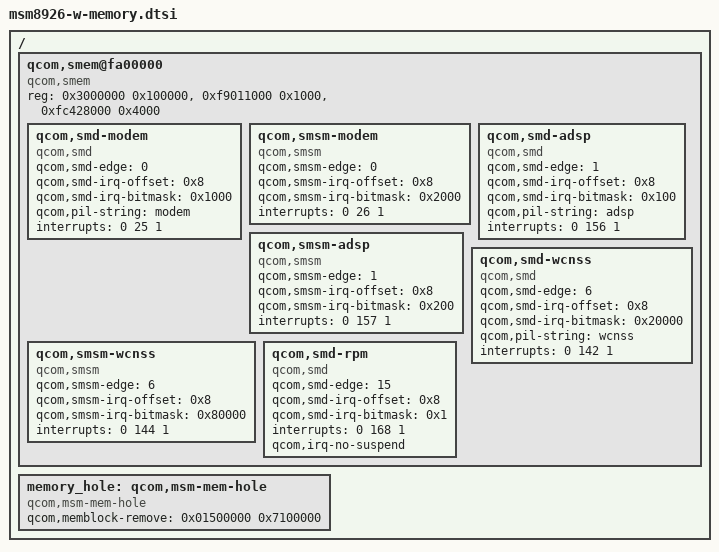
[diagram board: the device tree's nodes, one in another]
/* Copyright (c) 2015, The Linux Foundation. All rights reserved.
 *
 * This program is free software; you can redistribute it and/or modify
 * it under the terms of the GNU General Public License version 2 and
 * only version 2 as published by the Free Software Foundation.
 *
 * This program is distributed in the hope that it will be useful,
 * but WITHOUT ANY WARRANTY; without even the implied warranty of
 * MERCHANTABILITY or FITNESS FOR A PARTICULAR PURPOSE.  See the
 * GNU General Public License for more details.
 */

/ {
	qcom,smem@fa00000 {
		compatible = "qcom,smem";
		reg = <0x3000000 0x100000>,
			<0xf9011000 0x1000>,
			<0xfc428000 0x4000>;
		reg-names = "smem", "irq-reg-base", "aux-mem1";

		qcom,smd-modem {
			compatible = "qcom,smd";
			qcom,smd-edge = <0>;
			qcom,smd-irq-offset = <0x8>;
			qcom,smd-irq-bitmask = <0x1000>;
			qcom,pil-string = "modem";
			interrupts = <0 25 1>;
		};

		qcom,smsm-modem {
			compatible = "qcom,smsm";
			qcom,smsm-edge = <0>;
			qcom,smsm-irq-offset = <0x8>;
			qcom,smsm-irq-bitmask = <0x2000>;
			interrupts = <0 26 1>;
		};

		qcom,smd-adsp {
			compatible = "qcom,smd";
			qcom,smd-edge = <1>;
			qcom,smd-irq-offset = <0x8>;
			qcom,smd-irq-bitmask = <0x100>;
			qcom,pil-string = "adsp";
			interrupts = <0 156 1>;
		};

		qcom,smsm-adsp {
			compatible = "qcom,smsm";
			qcom,smsm-edge = <1>;
			qcom,smsm-irq-offset = <0x8>;
			qcom,smsm-irq-bitmask = <0x200>;
			interrupts = <0 157 1>;
		};

		qcom,smd-wcnss {
			compatible = "qcom,smd";
			qcom,smd-edge = <6>;
			qcom,smd-irq-offset = <0x8>;
			qcom,smd-irq-bitmask = <0x20000>;
			qcom,pil-string = "wcnss";
			interrupts = <0 142 1>;
		};

		qcom,smsm-wcnss {
			compatible = "qcom,smsm";
			qcom,smsm-edge = <6>;
			qcom,smsm-irq-offset = <0x8>;
			qcom,smsm-irq-bitmask = <0x80000>;
			interrupts = <0 144 1>;
		};

		qcom,smd-rpm {
			compatible = "qcom,smd";
			qcom,smd-edge = <15>;
			qcom,smd-irq-offset = <0x8>;
			qcom,smd-irq-bitmask = <0x1>;
			interrupts = <0 168 1>;
			qcom,irq-no-suspend;
		};
	};

	memory_hole: qcom,msm-mem-hole {
		compatible = "qcom,msm-mem-hole";
		qcom,memblock-remove = <0x01500000 0x7100000>; /* Address and Size of Hole */
	};
};
